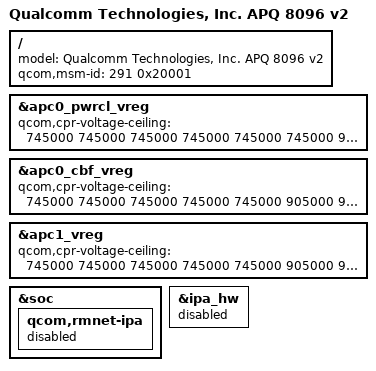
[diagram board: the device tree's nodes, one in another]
/* Copyright (c) 2014-2016, The Linux Foundation. All rights reserved.
 *
 * This program is free software; you can redistribute it and/or modify
 * it under the terms of the GNU General Public License version 2 and
 * only version 2 as published by the Free Software Foundation.
 *
 * This program is distributed in the hope that it will be useful,
 * but WITHOUT ANY WARRANTY; without even the implied warranty of
 * MERCHANTABILITY or FITNESS FOR A PARTICULAR PURPOSE.  See the
 * GNU General Public License for more details.
 */

/*
 * As a general rule, only version-specific property overrides should be placed
 * inside this file. Common device definitions should be placed inside the
 * msm8996.dtsi file.
 */

#include "msm8996-v2.dtsi"

/ {
	model = "Qualcomm Technologies, Inc. APQ 8096 v2";
	qcom,msm-id = <291 0x20001>;
};

&apc0_pwrcl_vreg {
	qcom,cpr-voltage-ceiling =
		<745000  745000  745000  745000  745000  745000  905000  905000
		 905000  905000  905000 1015000 1015000 1015000 1015000 1015000
		1015000 1015000 1015000>;
};

&apc0_cbf_vreg {
	qcom,cpr-voltage-ceiling =
	       <745000  745000  745000  745000  745000  905000  905000  905000
		905000 1015000>;
};

&apc1_vreg {
qcom,cpr-voltage-ceiling =
		<745000  745000  745000  745000  745000  905000  905000  905000
		 905000  905000  905000 1015000 1015000 1015000 1015000 1015000
		 1015000 1015000>;
};

&soc {
	qcom,rmnet-ipa {
		status = "disabled";
	};
};

&ipa_hw {
	status = "disabled";
};
